# RTS5918 register map
Vendor: Realtek Semiconductor Corp.; Series: RTS5918 Series; File version: 1.00
CPU: ARMV8MML r0p0, little endian, MPU, FPU, VTOR, 3 interrupt priority bits, 8 SAU regions
Registers are 32-bit, read-write, reset 0x0 unless marked. A register's access mark holds for its fields unless they carry their own. Offsets are from the block's base; [hi:lo] are bit positions; {n}, {i} and the like mark numbered series; 'fields as' and 'values as' point back to an identical list.

## ESPI — eSPI Controller
Base 0x40220000
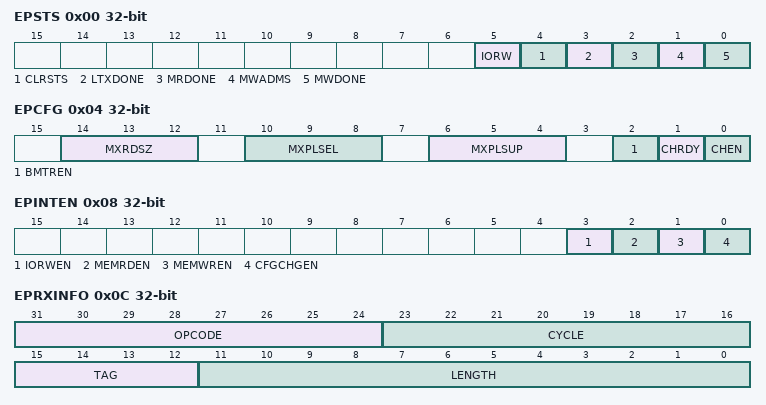
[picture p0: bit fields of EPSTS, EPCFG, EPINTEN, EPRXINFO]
0x00 EPSTS — PERIPHERAL CH. STATUS REGISTER
  [5] IORW write-1-clears — Peripheral Ch. IO R/W Short Status
    0=DO_NOTHING; 1=CLEAR (Clear Peripheral ch. IO R/W Short status)
  [4] CLRSTS write-1-clears — Peripheral Ch. Clear Status
    0=DO_NOTHING; 1=CLEAR (Clear Peripheral ch. status)
  [3] LTXDONE write-1-clears — Peripheral Ch. LTR Message Tx Done
    0=NOT_OCCURRED (Peripheral ch. LTR message tx done is not occurred); 1=OCCURRED (Peripheral ch. LTR message tx done is occurred)
  [2] MRDONE write-1-clears — Peripheral Ch. Memory Read Done
    0=NOT_OCCURRED (Peripheral ch. memory read done is not occurred); 1=OCCURRED (Peripheral ch. memory read done is occurred)
  [1] MWADMS write-1-clears — Peripheral Ch. Memory Address Mismatch
    0=NOT_OCCURRED (Peripheral ch. memory address mismatch is not occurred); 1=OCCURRED (Peripheral ch. memory address mismatch is occurred)
  [0] MWDONE write-1-clears — Peripheral Ch. Memory Write Done
    0=NOT_OCCURRED (Peripheral ch. memory write done is not occurred); 1=OCCURRED (Peripheral ch. memory write done is occurred)
0x04 EPCFG — PERIPHERAL CH. CONFIGURTAION REGISTER
  [14:12] MXRDSZ — Peripheral Ch. Maximum Read Request Size
    1=64B (64 bytes address aligned max read request size); 2=128B (128 bytes address aligned max read request size); 3=256B (256 bytes address aligned max read request size); 4=512B (512 bytes address aligned max read request size); 5=1024B (1024 bytes address aligned max read request size); 6=2048B (2048 bytes address aligned max read request size); 7=4096B (4096 bytes address aligned max read request size); other=NOT_USED (Reserved values. Do not use.)
  [10:8] MXPLSEL — Peripheral Ch. Maximum Payload Size Selected
    1=64B (64 bytes address aligned max payload size); 2=128B (128 bytes address aligned max payload size); 3=256B (256 bytes address aligned max payload size); other=NOT_USED (Reserved values. Do not use.)
  [6:4] MXPLSUP — Peripheral Ch. Maximum Payload Size Supported
    values as MXPLSEL
  [2] BMTREN — Peripheral Ch. Bus Master Enable
    0=DISABLE (Peripheral ch. bus mastering is disable); 1=ENABLE (Peripheral ch. bus mastering is enable)
  [1] CHRDY — Peripheral Ch. Ready
    0=NOT_READY (Peripheral ch. is not ready); 1=READY (Peripheral ch. is ready)
  [0] CHEN — Peripheral Ch. Enable
    0=DISABLE (Peripheral ch. is disable); 1=ENABLE (Peripheral ch. is enable)
0x08 EPINTEN — PERIPHERAL CH. INTERRUPT ENABLE REGISTER
  [3] IORWEN — Peripheral Ch. IO R/W Short Interrupt Enable
    0=DISABLE (Disable peripheral ch. IO R/W Short interrupt); 1=ENABLE (Enable peripheral ch. IO R/W Short interrupt)
  [2] MEMRDEN — Peripheral Ch. Memory Read Interrupt Enable
    0=DISABLE (Disable peripheral ch. memory read interrupt); 1=ENABLE (Enable peripheral ch. memory read interrupt)
  [1] MEMWREN — Peripheral Ch. Memory Write Interrupt Enable
    0=DISABLE (Disable peripheral ch. memory write interrupt); 1=ENABLE (Enable peripheral ch. memory write interrupt)
  [0] CFGCHGEN — Peripheral Ch. Configuration Change Interrupt Enable
    0=DISABLE (Disable peripheral ch. config change interrupt); 1=ENABLE (Enable peripheral ch. config change interrupt)
0x0C EPRXINFO ro — PERIPHERAL CH. RECEIVE PACKET INFORMATION REGISTER
  [31:24] OPCODE — Peripheral Ch. RX Command Opcode
  [23:16] CYCLE — Peripheral Ch. RX Command Cycle
  [15:12] TAG — Peripheral Ch. RX Command Tag
  [11:0] LENGTH — Peripheral Ch. Rx Command Length
0x10 EPRXADRH — PERIPHERAL CH. RECEIVE ADDRESS HIGH REGISTER
0x14 EPRXADRL — PERIPHERAL CH. RECEIVE ADDRESS LOW REGISTER
0x18 EPCPRADR — PERIPHERAL CH. COMPARE ADDRESS REGISTER
0x1C EPCPRVLD — PERIPHERAL CH. COMPARE ADDRESS VALID REGISTER
  [0] VALIDEN — Peripheral Ch. Memory Write Address Compare Enable
    0=IGNORE (Ignore peripheral ch. memory write address); 1=COMAPRE (Compare peripheral ch. memory write address)
0x20 EPBUF — PERIPHERAL CH. BUFFER REGISTER
0x24 EPBUFSZ — PERIPHERAL CH. BUFFER SIZE REGISTER
  [3:0] SIZE — Peripheral Ch. Memory Buffer Size
    0=x16 (x16 payload size); 1=x1 payload size; {v}=x{v} (x{v} payload size) (v=2..9); 10=x10 payload size; 11=x11 payload size; {v}=x{v} (x{v} payload size) (v=12..15)
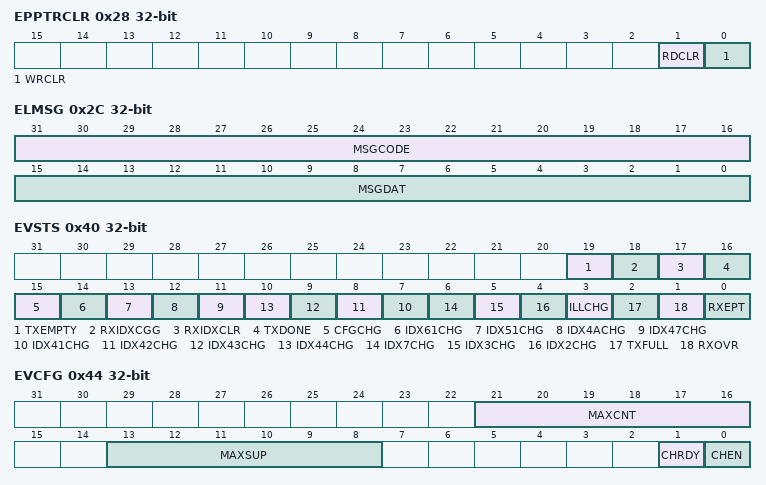
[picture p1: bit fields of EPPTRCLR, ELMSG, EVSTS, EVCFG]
0x28 EPPTRCLR — PERIPHERAL CH. POINTER CLEAR REGISTER
  [1] RDCLR write-1-clears — Reset Peripheral Ch. Memory Read Pointer
    0=DO_NOTHING; 1=RESET (Reset peripheral ch. read pointer)
  [0] WRCLR write-1-clears — Reset Peripheral Ch. Memory Write Pointer
    0=DO_NOTHING; 1=RESET (Reset peripheral ch. write pointer)
0x2C ELMSG — PERIPHERAL CH. LTR MESSAGE REGISTER
  [31:16] MSGCODE — Code of LTR Message to be Transfered
  [15:0] MSGDAT — Data of LTR Message to be Transfered
0x30 EPMRDA — PERIPHERAL CH. MEMORY RECEIVE DATA REGISTER
0x34 EPMRADRL — PERIPHERAL CH. MEMORY RECEIVE ADDRESS LOW REGISTER
0x38 EPMRADRH — PERIPHERAL CH. MEMORY RECEIVE ADDRESS HIGH REGISTER
0x3C EPMRLEN — PERIPHERAL CH. MEMORY RECEIVE LENGTH REGISTER
  [11:0] RXLEN — Peripheral Ch. Memory Receive Length
0x40 EVSTS — VIRTUAL WIRE CH. STATUS REGISTER
  [19] TXEMPTY — Virtual Wire Ch. Tx FIFO Empty
    0=NOT_EMPTY (Virtual wire ch. Tx FIFO is not empty); 1=EMPTY (Virtual wire ch. Tx FIFO is empty)
  [18] RXIDXCGG write-1-clears — Virtual Wire Ch. Rx Changed
  [17] RXIDXCLR write-1-clears — Virtual Wire Ch. Rx Index Clear
  [16] TXDONE write-1-clears — Virtual Wire Ch. Transaction Done
    0=NOT_OCCURRED (Virtual wire ch. transaction done is not occurred); 1=OCCURRED (Virtual wire ch. transaction done is occurred)
  [15] CFGCHG write-1-clears — Virtual Wire Ch. Configuration Changed
    0=NOT_CHANGED (Virtual wire ch. configuration is not changed); 1=CHANGED (Virtual wire ch. configuration is changed)
  [14] IDX61CHG write-1-clears — Virtual Wire Ch. Index61 Changed
    0=NOT_CHANGED (Virtual wire ch. index is not changed); 1=CHANGED (Virtual wire ch. index is changed)
  [13] IDX51CHG write-1-clears — Virtual Wire Ch. Index51 Changed
    values as IDX61CHG
  [12] IDX4ACHG write-1-clears — Virtual Wire Ch. Index4A Changed
    values as IDX61CHG
  [11] IDX47CHG write-1-clears — Virtual Wire Ch. Index47 Changed
    values as IDX61CHG
  [n-34] IDX{n}CHG write-1-clears (n=41..44) — Virtual Wire Ch. Index{n} Changed
    values as IDX61CHG
  [6] IDX7CHG write-1-clears — Virtual Wire Ch. Index7 Changed
    values as IDX61CHG
  [5] IDX3CHG write-1-clears — Virtual Wire Ch. Index3 Changed
    values as IDX61CHG
  [4] IDX2CHG write-1-clears — Virtual Wire Ch. Index2 Changed
    values as IDX61CHG
  [3] ILLCHG write-1-clears — Virtual Wire Ch. Illegal Index
    0=NOT_ILLEGAL (Virtual wire ch. Tx index is not illegal); 1=ILLEGAL (Virtual wire ch. Tx index is illegal)
  [2] TXFULL ro — Virtual Wire Ch. Tx FIFO Full
    0=NOT_FULL (Virtual wire ch. Tx FIFO is not full); 1=FULL (Virtual wire ch. Tx FIFO is full)
  [1] RXOVR write-1-clears — Virtual Wire Ch. Rx FIFO Overrun
    0=NOT_OV (Virtual wire ch. Rx FIFO is not overrun); 1=OV (Virtual wire ch. Rx FIFO is overrun)
  [0] RXEPT ro — Virtual Wire Ch. Rx FIFO Empty
    0=NOT_EMPTY (Virtual wire ch. Rx FIFO is not empty); 1=EMPTY (Virtual wire ch. Rx FIFO is empty)
0x44 EVCFG — VIRTUAL WIRE CH. CONFIGURATION REGISTER
  [21:16] MAXCNT ro — Virtual Wire Ch. Maximum Operating Count
  [13:8] MAXSUP ro — Virtual Wire Ch. Maximum Count Supported
  [1] CHRDY — Virtual Wire Ch. Ready
    0=NOT_READY (Virtual Wire ch. is not ready); 1=READY (Virtual Wire ch. is ready)
  [0] CHEN — Virtual Wire Ch. Enable
    0=DISABLE (Virtual Wire ch. is disable); 1=ENABLE (Virtual Wire ch. is enable)
0x48 EVIDX2 — VIRTUAL WIRE CH. RX INDEX 2 REGISTER
  [7:0] RXDAT ro — Virtual Wire Ch. Index2 Receive Data
0x4C EVIDX3 — VIRTUAL WIRE CH. RX INDEX 3 REGISTER
  [7:0] RXDAT ro — Virtual Wire Ch. Index3 Receive Data
0x50 EVIDX7 — VIRTUAL WIRE CH. RX INDEX 7 REGISTER
  [7:0] RXDAT ro — Virtual Wire Ch. Index7 Receive Data
0x54 EVIDX41 — VIRTUAL WIRE CH. RX INDEX 41 REGISTER
  [7:0] RXDAT ro — Virtual Wire Ch. Index41 Receive Data
0x58 EVIDX42 — VIRTUAL WIRE CH. RX INDEX 42 REGISTER
  [7:0] RXDAT ro — Virtual Wire Ch. Index42 Receive Data
0x5C EVIDX43 — VIRTUAL WIRE CH. RX INDEX 43 REGISTER
  [7:0] RXDAT ro — Virtual Wire Ch. Index43 Receive Data
0x60 EVIDX44 — VIRTUAL WIRE CH. RX INDEX 44 REGISTER
  [7:0] RXDAT ro — Virtual Wire Ch. Index44 Receive Data
0x64 EVIDX47 — VIRTUAL WIRE CH. RX INDEX 47 REGISTER
  [7:0] RXDAT ro — Virtual Wire Ch. Index47 Receive Data
0x68 EVIDX4A — VIRTUAL WIRE CH. RX INDEX 4A REGISTER
  [7:0] RXDAT ro — Virtual Wire Ch. Index4A Receive Data
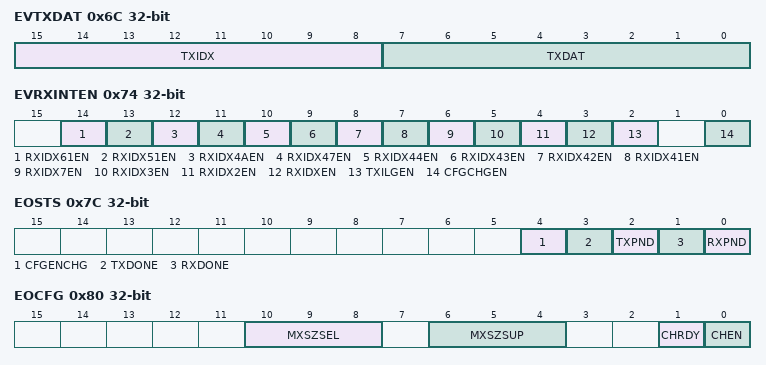
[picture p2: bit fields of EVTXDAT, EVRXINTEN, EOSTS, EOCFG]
0x6C EVTXDAT — VIRTUAL WIRE CH. TX DATA REGISTER
  [15:8] TXIDX — Virtual Wire Ch. Transport Index
  [7:0] TXDAT — Virtual Wire Ch. Transport Data
0x70 EVPVIDX — VIRTUAL WIRE CH. PRIVILEGE INDEX REGISTER
  [7:0] PVIDX ro — Virtual Wire Ch. Transport Privilege Index
0x74 EVRXINTEN — VIRTUAL WIRE CH. RX INTERRUPT ENABLE REGISTER
  [14] RXIDX61EN — Virtual Wire Ch. Recevie Index61 Data Change Interrupt Enable
    0=DISABLE (Disable virtual wire ch. recevice index61 data change interrupt); 1=ENABLE (Enable virtual wire ch. recevice index61 data change interrupt)
  [13] RXIDX51EN — Virtual Wire Ch. Recevie Index51 Data Change Interrupt Enable
    0=DISABLE (Disable virtual wire ch. recevice index51 data change interrupt); 1=ENABLE (Enable virtual wire ch. recevice index51 data change interrupt)
  [12] RXIDX4AEN — Virtual Wire Ch. Recevie Index4A Data Change Interrupt Enable
    0=DISABLE (Disable virtual wire ch. recevice index4A data change interrupt); 1=ENABLE (Enable virtual wire ch. recevice index4A data change interrupt)
  [11] RXIDX47EN — Virtual Wire Ch. Recevie Index47 Data Change Interrupt Enable
    0=DISABLE (Disable virtual wire ch. recevice index47 data change interrupt); 1=ENABLE (Enable virtual wire ch. recevice index47 data change interrupt)
  [10] RXIDX44EN — Virtual Wire Ch. Recevie Index44 Data Change Interrupt Enable
    0=DISABLE (Disable virtual wire ch. recevice index43 data change interrupt); 1=ENABLE (Enable virtual wire ch. recevice index44 data change interrupt)
  [9] RXIDX43EN — Virtual Wire Ch. Recevie Index43 Data Change Interrupt Enable
    0=DISABLE (Disable virtual wire ch. recevice index43 data change interrupt); 1=ENABLE (Enable virtual wire ch. recevice index43 data change interrupt)
  [8] RXIDX42EN — Virtual Wire Ch. Recevie Index42 Data Change Interrupt Enable
    0=DISABLE (Disable virtual wire ch. recevice index42 data change interrupt); 1=ENABLE (Enable virtual wire ch. recevice index42 data change interrupt)
  [7] RXIDX41EN — Virtual Wire Ch. Recevie Index41 Data Change Interrupt Enable
    0=DISABLE (Disable virtual wire ch. recevice index41 data change interrupt); 1=ENABLE (Enable virtual wire ch. recevice index41 data change interrupt)
  [6] RXIDX7EN — Virtual Wire Ch. Recevie Index7 Data Change Interrupt Enable
    0=DISABLE (Disable virtual wire ch. recevice index7 data change interrupt); 1=ENABLE (Enable virtual wire ch. recevice index7 data change interrupt)
  [5] RXIDX3EN — Virtual Wire Ch. Recevie Index3 Data Change Interrupt Enable
    0=DISABLE (Disable virtual wire ch. recevice index3 data change interrupt); 1=ENABLE (Enable virtual wire ch. recevice index3 data change interrupt)
  [4] RXIDX2EN — Virtual Wire Ch. Recevie Index2 Data Change Interrupt Enable
    0=DISABLE (Disable virtual wire ch. recevice index2 data change interrupt); 1=ENABLE (Enable virtual wire ch. recevice index2 data change interrupt)
  [3] RXIDXEN — Virtual Wire Ch. Recevie Other Index Data Change Interrupt Enable
    0=DISABLE (Disable virtual wire ch. recevice other index data change interrupt); 1=ENABLE (Enable virtual wire ch. recevice other index data change interrupt)
  [2] TXILGEN — Virtual Wire Ch. TX Illegal Interrupt Enable
    0=DISABLE (Disable virtual wire TX Illegal interrupt); 1=ENABLE (Enable virtual wire TX Illegal interrupt)
  [0] CFGCHGEN — Virtual Wire Ch. Configuration Change Interrupt Enable
    0=DISABLE (Disable virtual wire ch. config change interrupt); 1=ENABLE (Enable virtual wire ch. config change interrupt)
0x78 EVTXINTEN — VIRTUAL WIRE CH. TX INTERRUPT ENABLE REGISTER
  [0] TXMPTEN — Virtual Wire Ch. Tx FIFO Empty Interrupt Enable
    0=DISABLE (Disable virtual wire ch. tx FIFO empty interrupt); 1=ENABLE (Enable virtual wire ch. tx FIFO empty interrupt)
0x7C EOSTS — OOB CH. STATUS REGISTER
  [4] CFGENCHG — OOB Ch. Configuration Channel Enable Changed
    0=NOT_OCCURRED (OOB ch. configuration channel enable changed is not occurred); 1=OCCURRED (OOB ch. configuration channel enable changed is occurred)
  [3] TXDONE write-1-clears — OOB Ch. Transaction Done
    0=NOT_OCCURRED (OOB ch. transaction done is not occurred); 1=OCCURRED (OOB ch. transaction done is occurred)
  [2] TXPND ro — OOB Ch. TX FIFO Pending
    0=NOT_PENDING (Have no data in Tx FIFO); 1=PENDING (Have data in Tx FIFO, waiting for transaction)
  [1] RXDONE write-1-clears — OOB Ch. Receive Done
    0=NOT_OCCURRED (OOB ch. recevie done is not occurred); 1=OCCURRED (OOB ch. recevie done is occurred)
  [0] RXPND ro — OOB Ch. RX FIFO Pending
    0=NOT_PENDING (Have no data in Rx FIFO); 1=PENDING (Have data in Rx FIFO)
0x80 EOCFG — OOB CH. CONFIGURATION REGISTER
  [10:8] MXSZSEL ro — OOB Ch. Maximum Payload Size Selected
    1=64B (64 bytes max payload size); 2=128B (128 bytes max payload size); 3=256B (256 bytes max payload size); other=NOT_USED (Reserved values. Do not use.)
  [6:4] MXSZSUP ro — OOB Ch. Maximum Payload Size Supported
    values as MXSZSEL
  [1] CHRDY — OOB Ch. Ready
    0=NOT_READY (OOB ch. is not ready); 1=READY (OOB ch. is ready)
  [0] CHEN — OOB Ch. Enable
    0=DISABLE (OOB ch. is disable); 1=ENABLE (OOB ch. is enable)
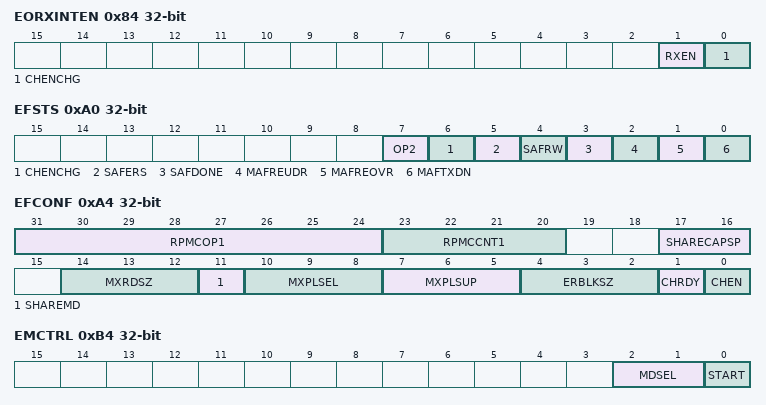
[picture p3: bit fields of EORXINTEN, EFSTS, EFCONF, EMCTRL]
0x84 EORXINTEN — OOB CH. RX INTERRUPT ENABLE REGISTER
  [1] RXEN — OOB Ch. Rx Interrupt Enable
    0=DISABLE (Disable OOB ch. rx interrupt); 1=ENABLE (Enable OOB ch. rx interrupt)
  [0] CHENCHG — OOB Ch. Configuration Channel Enable Changed Interrupt Enable
    0=DISABLE (Disable OOB ch. configuration channel enable changed interrupt); 1=ENABLE (Enable OOB ch. configuration channel enable changed interrupt)
0x88 EORXBUF — OOB CH. RX BUFFER REGISTER
0x8C EORXLEN — OOB CH. RX LENGTH REGISTER
  [11:0] LENGTH — OOB Ch. Rx Length
0x90 EOTXBUF — OOB CH. TX BUFFER REGISTER
0x94 EOTXLEN — OOB CH. TX LENGTH REGISTER
  [7:0] LENGTH — OOB Ch. Tx Length
0x98 EOTXCTRL — OOB CH. TX CONTROL REGISTER
  [0] TXSTR — Kick OOB Ch. Start to Transaction
0x9C EOTXINTEN — OOB CH. TX INTERRUPT ENABLE REGISTER
  [0] TXEN — OOB Ch. Tx Interrupt Enable
    0=DISABLE (Disable OOB ch. tx interrupt); 1=ENABLE (Enable OOB ch. tx interrupt)
0xA0 EFSTS — FLASH CH. STATUS REGISTER
  [7] OP2 — Flash Ch. Receive RPMC OP2 Command
    0=NOT_OCCURRED (Flash Ch. have not received RPMC OP2 command); 1=OCCURRED (Flash Ch. have received RPMC OP2 command)
  [6] CHENCHG — Flash Ch. Configuration Channel Enable Changed
    0=NOT_OCCURRED (Flash ch. configuration channel enable changed is not occurred); 1=OCCURRED (Flash ch. configuration channel enable changed is occurred)
  [5] SAFERS write-1-clears — Flash Ch. SAF Transfer Type Erase
    0=NOT_OCCURRED (Flash ch. SAF transfer type erase is not occurred); 1=OCCURRED (Flash ch. SAF transfer type erase is occurred)
  [4] SAFRW — Flash Ch. SAF Transfer Type
    0=READ (Flash ch. SAF transfer type is read); 1=WRITE (Flash ch. SAF transfer type is write)
  [3] SAFDONE write-1-clears — Flash Ch. SAF Transfer Done
    0=NOT_OCCURRED (Flash ch. SAF transfer done is not occurred); 1=OCCURRED (Flash ch. SAF transfer done is occurred)
  [2] MAFREUDR write-1-clears — Flash Ch. MAF Underrun
    0=NOT_OCCURRED (Flash ch. MAF underrun is not occurred); 1=OCCURRED (Flash ch. MAF underrun is occurred)
  [1] MAFREOVR write-1-clears — Flash Ch. MAF Overrun
    0=NOT_OCCURRED (Flash ch. MAF overrun is not occurred); 1=OCCURRED (Flash ch. MAF overrun is occurred)
  [0] MAFTXDN write-1-clears — Flash Ch. MAF Transfer Done
    0=NOT_OCCURRED (Flash ch. MAF transfer done is not occurred); 1=OCCURRED (Flash ch. MAF transfer done is occurred)
0xA4 EFCONF — FLASH CH. CONFIGURATION REGISTER
  [31:24] RPMCOP1 — RPMC OP1 Opcode on the 1st RPMC Flash device
  [23:20] RPMCCNT1 — RPMC Counter on the 1st RPMC Flash device
  [17:16] SHARECAPSP — Flash Sharing Capability Supported
    2=SAF (Target attached flash sharing supported); 3=SAF_MAF (Both target/controller attached flash sharing supported); other=MAF (Controller attached flash sharing supported)
  [14:12] MXRDSZ — Flash Access Channel Maximum Read Request Size
    values as EPCFG.MXRDSZ
  [11] SHAREMD — Flash Sharing Mode
    0=MAF (Controller attached flash sharing); 1=SAF (Target attached flash sharing)
  [10:8] MXPLSEL — Flash Access Channel Maximum Payload Size Selected
    1=64KB (64 bytes max payload size); 2=128KB (128 bytes max payload size); 3=256KB (256 bytes max payload size); other=NOT_USED (Reserved values. Do not use.)
  [7:5] MXPLSUP — Flash Access Channel Maximum Payload Size Supported
    values as MXPLSEL
  [4:2] ERBLKSZ — Flash Block Erase Size
    1=4KB (4 Kbytes); 2=64KB (64 Kbytes); 3=4KB_64KB (Both 4 Kbytes and 64 Kbytes); 4=128KB (128 Kbytes); 5=256KB (256 Kbytes); other=NOT_USED (Reserved values. Do not use.)
  [1] CHRDY — Flash Access Ch. Ready
    0=NOT_READY (Flash access ch. is not ready); 1=READY (Flash access ch. is ready)
  [0] CHEN — Flash Access Ch. Enable
    0=DISABLE (Flash access ch. is disable); 1=ENABLE (Flash access ch. is enable)
0xA8 EMADR — FLASH CH. MAF FLASH ADDRESS REGISTER
0xAC EMTRLEN — FLASH CH. MAF TRANSFER LENGTH REGISTER
  [11:0] TRLEN — Flash Ch. MAF Tx Length
0xB0 EMBUF — FLASH CH. MAF BUFFER REGISTER
0xB4 EMCTRL — FLASH CH. MAF CONTROL REGISTER
  [2:1] MDSEL — Flash Ch. MAF TR Mode selection
    0=TR_READ (Perform MAF read transaction); 1=TR_WRITE (Perform MAF write transactiond); 2=TR_ERASE (Perform MAF erase transaction); other=NOT_USED (Reserved values. Do not use.)
  [0] START — Kick Flash Ch. MAF Start to Transaction
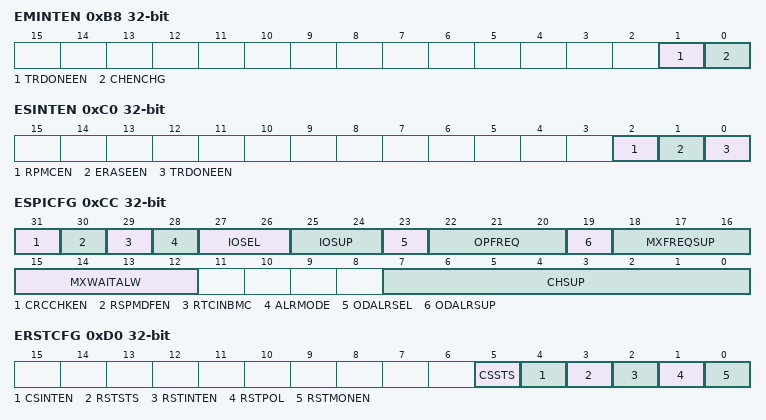
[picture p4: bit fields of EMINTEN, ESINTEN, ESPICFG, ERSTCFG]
0xB8 EMINTEN — FLASH CH. MAF INTERRUPT ENABLE REGISTER
  [1] TRDONEEN — Flash Ch. MAF Transfer Done Interrupt Enable
    0=DISABLE (Disable flash ch. MAF transfer done interrupt); 1=ENABLE (Enable flash ch. MAF transfer done interrupt)
  [0] CHENCHG — Flash Ch. Configuration Channel Enable Changed Interrupt Enable
    0=DISABLE (Disable flash ch. configuration channel enable changed interrupt); 1=ENABLE (Enable flash ch. configuration channel enable changed interrupt)
0xBC ESBUF — FLASH CH. SAF BUFFER REGISTER #0
0xC0 ESINTEN — FLASH CH. SAF INTERRUPT ENABLE REGISTER
  [2] RPMCEN — Flash Ch. SAF RPMC OP2 Interrupt Enable
    0=DISABLE (Disable flash ch. SAF RPMC op2 interrupt); 1=ENABLE (Enable flash ch. SAF RPMC op2 interrupt)
  [1] ERASEEN — Flash Ch. SAF Erase Interrupt Enable
    0=DISABLE (Disable flash ch. SAF erase interrupt); 1=ENABLE (Enable flash ch. SAF erase interrupt)
  [0] TRDONEEN — Flash Ch. SAF Transfer Done Interrupt Enable
    0=DISABLE (Disable flash ch. SAF transfer done interrupt); 1=ENABLE (Enable flash ch. SAF transfer done interrupt)
0xC4 ESRXADR — FLASH CH. SAF RECEIVE ADDRESS REGISTER
0xC8 ESRXLEN — FLASH CH. SAF RECEIVE LENGTH REGISTER
  [11:0] LENGTH ro — Peripheral Ch. RX Command Length
0xCC ESPICFG — GENERAL CONFIGURATION REGISTER
  [31] CRCCHKEN — CRC Checking Enable
    0=DISABLE (Disable CRC checking); 1=ENABLE (Enable CRC checking)
  [30] RSPMDFEN — Response Modifier Enable
    0=DISABLE (Disable the use of Response Modifier); 1=ENABLE (Enable the use of Response Modifier)
  [29] RTCINBMC — RTC-Integrated-BMC
    0=NOT_SUPPORTED (BMC does not support an integrated RTC); 1=SUPPORTED (BMC supports an integrated RTC)
  [28] ALRMODE — Alert Mode
    0=IO1_PIN (I/O[1] pin is used to signal the alert event); 1=ALERT_PIN (Alert# pin is used to signal the alert event)
  [27:26] IOSEL — I/O Mode Select
    0=SINGLE (Single I/O Select); 1=DUAL (Dual I/O Select); 2=QUAD (Quad I/O Select); other=NOT_USED (Reserved values. Do not use.)
  [25:24] IOSUP — I/O Mode Support
    0=SINGLE (Single I/O supported); 1=SINGLE_DUAL (Single and Dual I/O supported); 2=SINGLE_QUAD (Single and Quad I/O supported); 3=SINGLE_DUAL_QUAD (Single, Dual and Dual I/O supported)
  [23] ODALRSEL — Open Drain Alert Select
    0=OUTPUT (Alert# pin is a driven output); 1=OPEN_DRAIN (Alert# pin is an open-drain output)
  [22:20] OPFREQ — Operating Frequency
    0=20MHz (Operating frequency is 20MHz); 1=25MHz (Operating frequency is 25MHz); 2=33MHz (Operating frequency is 33MHz); 3=50MHz (Operating frequency is 50MHz); 4=66MHz (Operating frequency is 66MHz); other=NOT_USED (Reserved values. Do not use.)
  [19] ODALRSUP — Open Drain Alert Supported
    0=NOT_SUPPORTED (Open-drain Alert# pin is not supported); 1=SUPPORTED (Open-drain Alert# pin is supported)
  [18:16] MXFREQSUP — Maximum Frequency Supported
    0=20MHz (Maximum operating frequency is 20MHz); 1=25MHz (Maximum operating frequency is 25MHz); 2=33MHz (Maximum operating frequency is 33MHz); 3=50MHz (Maximum operating frequency is 50MHz); 4=66MHz (Maximum operating frequency is 66MHz); other=NOT_USED (Reserved values. Do not use.)
  [15:12] MXWAITALW — Maximum WAIT STATE Allowed
  [7:0] CHSUP — Channel Supported
0xD0 ERSTCFG — RESET PIN INTERRUPT CONFIGURATION REGISTER
  [5] CSSTS — eSPI CS Pin Status
  [4] CSINTEN — eSPI CS Pin Interrupt Enable
    0=DISABLE (Disable eSPI CS pin interrupt); 1=ENABLE (Enable eSPI CS pin interrupt)
  [3] RSTSTS — eSPI Reset Pin Status
  [2] RSTINTEN — eSPI Reset Pin Interrupt Enable
    0=DISABLE (Disable eSPI reset pin interrupt); 1=ENABLE (Enable eSPI reset pin interrupt)
  [1] RSTPOL — eSPI Reset Pin Polarity
    0=RISING (Rising-edge(low-to-high) on reset pin trigger interrupt); 1=FALLING (Falling-edge(high-to-low) on reset pin trigger interrupt)
  [0] RSTMONEN — eSPI Reset Pin Monitor Enable
    0=DISABLE (Disable eSPI reset pin monitor); 1=ENABLE (Enable eSPI reset pin monitor)
0xD4 EVIDX51 — VIRTUAL WIRE CH. RX INDEX 51 REGISTER
  [7:0] RXDAT ro — Virtual Wire Ch. Index51 Receive Data
0xD8 EVIDX61 — VIRTUAL WIRE CH. RX INDEX 61 REGISTER
  [7:0] RXDAT ro — Virtual Wire Ch. Index61 Receive Data
0xDC ESRXC — FLASH CH. SAF RECEIVE CYCLE TYPE REGISTER
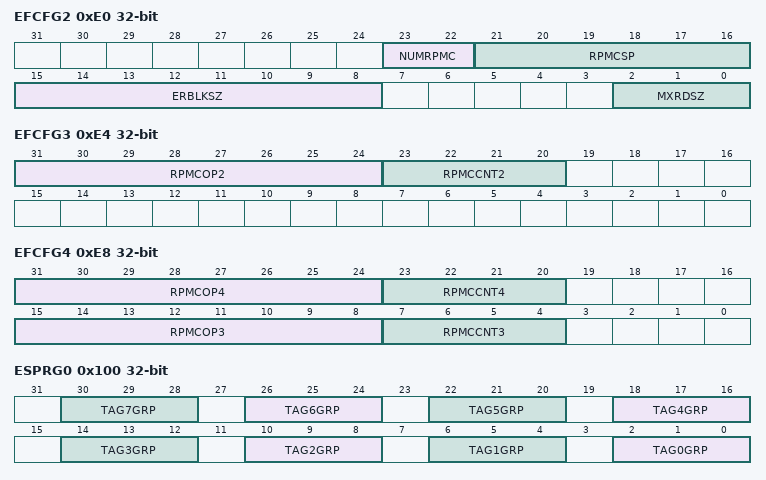
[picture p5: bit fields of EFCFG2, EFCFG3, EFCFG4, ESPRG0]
0xE0 EFCFG2 — FLASH CH. SAF CONFIG #2 REGISTER
  [23:22] NUMRPMC — Number of Target Attached Flash RPMC flash devices
    0=x1 RPMC flash device is supported; 1=x2 (x2 RPMC flash device is supported); 2=x3 (x3 RPMC flash device is supported); 3=x4 (x4 RPMC flash device is supported)
  [21:16] RPMCSP — Target RPMC Supported
  [15:8] ERBLKSZ — Target Flash Erase Block Size
  [2:0] MXRDSZ — Target Maximum Read Request Size Supported
    2=128B (128 bytes max read request size); 3=256B (256 bytes max read request size); 4=512B (512 bytes max read request size); 5=1024B (1024 bytes max read request size); 6=2048B (2048 bytes max read request size); 7=4096B (4096 bytes max read request size); other=64B (64 bytes max read request size)
0xE4 EFCFG3 — FLASH CH. SAF CONFIG #3 REGISTER
  [31:24] RPMCOP2 — RPMC OP1 Opcode on the 2nd RPMC Flash device
  [23:20] RPMCCNT2 — RPMC Counter on the 2nd RPMC Flash device
0xE8 EFCFG4 — FLASH CH. SAF CONFIG #4 REGISTER
  [31:24] RPMCOP4 — RPMC OP1 Opcode on the 4th RPMC Flash device
  [23:20] RPMCCNT4 — RPMC Counter on the 4th RPMC Flash device
  [15:8] RPMCOP3 — RPMC OP1 Opcode on the 3rd RPMC Flash device
  [7:4] RPMCCNT3 — RPMC Counter on the 3rd RPMC Flash device
0xF8 ELCTRL — PERIPHERAL CH. LTR CONTROL REGISTER
  [0] TXSTR — Kick LTR Start to Transaction
0xFC ESBUF1 — FLASH CH. SAF RPMC BUFFER1 REGISTER
0x100 ESPRG0 — FLASH CH. SAF PROTECTION GROUP #0 REGISTER
  [4n+2:4n] TAG{n}GRP (n=0..7) — Tag #{n} Group
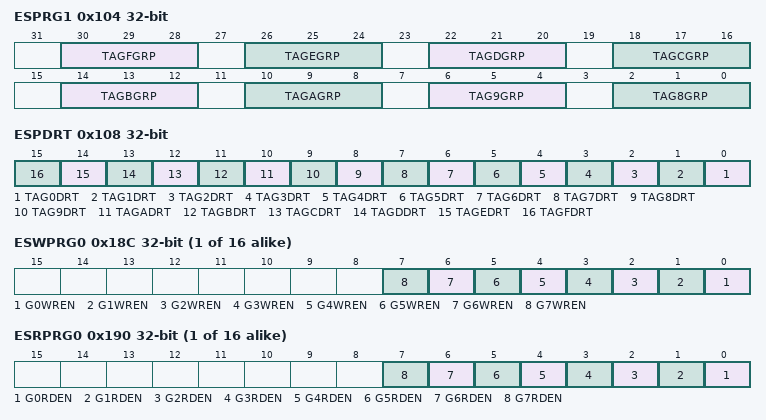
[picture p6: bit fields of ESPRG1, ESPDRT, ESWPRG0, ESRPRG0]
0x104 ESPRG1 — FLASH CH. SAF PROTECTION GROUP #1 REGISTER
  [30:28] TAGFGRP — Tag #F Group
  [26:24] TAGEGRP — Tag #E Group
  [22:20] TAGDGRP — Tag #D Group
  [18:16] TAGCGRP — Tag #C Group
  [14:12] TAGBGRP — Tag #B Group
  [10:8] TAGAGRP — Tag #A Group
  [6:4] TAG9GRP — Tag #9 Group
  [2:0] TAG8GRP — Tag #8 Group
0x108 ESPDRT — FLASH CH. SAF PROTECTION DIRTY REGISTER
  [0] TAG{x}DRT (x=0,1,2,3,4,5,6,7,8,9,A,B,C,D,E,F; step 1) — Tag #{x} Dirty
    0=NOT_DIRTY (Contents of Region are not dirty); 1=DIRTY (Contents of Region are dirty)
0x10C ESP{x}STR (x=0,1,2,3,4,5,6,7,8,9,A,B,C,D,E,F; step 0x4) — FLASH CH. SAF REGION #{x} START REGISTER
  [19:0] ADDR — Region Start Address
0x14C ESP{x}LEN (x=0,1,2,3,4,5,6,7,8,9,A,B,C,D,E,F; step 0x4) — FLASH CH. SAF REGION #{x} LENGTH REGISTER
  [19:0] LEN — Region Length
0x18C ESWPRG{x} (x=0,1,2,3,4,5,6,7,8,9,A,B,C,D,E,F; step 0x8) — FLASH CH. SAF WRITE PROTECTION REGION #{x} REGISTER
  [n] G{n}WREN (n=0..7) — Group #{n} Write Enable
0x190 ESRPRG{x} (x=0,1,2,3,4,5,6,7,8,9,A,B,C,D,E,F; step 0x8) — FLASH CH. SAF READ PROTECTION REGION #{x} REGISTER
  [n] G{n}RDEN (n=0..7) — Group #{n} Read Enable
0x20C ESPREN — FLASH CH. SAF PROTECTION ENABLE REGISTER
  [0] EN — Flash Ch. SAF Protection Enable
    0=DISABLE (Disable flash ch. SAF protection); 1=ENABLE (Enable flash ch. SAF protection)
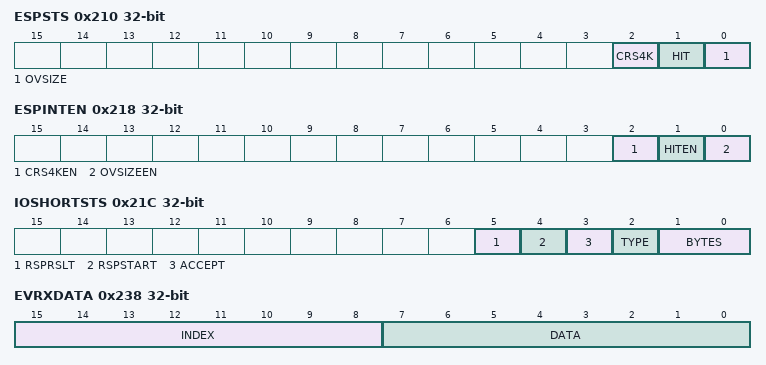
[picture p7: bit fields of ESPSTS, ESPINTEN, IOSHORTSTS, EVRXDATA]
0x210 ESPSTS — FLASH CH. SAF PROTECTION STATUS REGISTER
  [2] CRS4K write-1-clears — Host Cross 4K boundary
    0=NOT_OCCURRED (Host cross 4K boundary is not occurred); 1=OCCURRED (Host cross 4K boundary is occurred)
  [1] HIT write-1-clears — Host Hit Protection Region
    0=NOT_OCCURRED (Host hit protection region is not occurred); 1=OCCURRED (Host hit protection region is occurred)
  [0] OVSIZE write-1-clears — Host Access Over Size
    0=NOT_OCCURRED (Host access over size is not occurred); 1=OCCURRED (Host access over size is occurred)
0x214 ESFLSZ — FLASH CH. SAF FLASH SIZE REGISTER
0x218 ESPINTEN — FLASH CH. SAF PROTECTION INTERRUPT ENABLE REGISTER
  [2] CRS4KEN write-1-clears — Host Cross 4K Boundary Interrupt Enable
    0=DISABLE (Disable host cross 4K boundary interrupt); 1=ENABLE (Enable cross 4K boundary interrupt)
  [1] HITEN write-1-clears — Host Hit Protection Region Interrupt Enable
    0=DISABLE (Disable host hit protection region interrupt); 1=ENABLE (Enable host hit protection region interrupt)
  [0] OVSIZEEN write-1-clears — Host Access Over Size Interrupt Enable
    0=DISABLE (Disable host access over size interrupt); 1=ENABLE (Enable host access over size interrupt)
0x21C IOSHORTSTS — IO SHORT STATUS REGISTER
  [5] RSPRSLT — IO Short Read/Write Response Result
    0=SUCCESS (IO short read/write response successful); 1=UNSUCCESS (IO short read/write response unsuccessful)
  [4] RSPSTART — IO Short Read/Write Response Start
    0=NONE (IO short read/write response pending); 1=START (IO short read/write response start)
  [3] ACCEPT write-1-clears — IO Short Read/Write Accpeted
    0=NOT_OCCURRED (IO short read/write accpeted is not occurred); 1=OCCURRED (IO short read/write accpeted is occurred)
  [2] TYPE — Type of IO Short
    0=READ (Peripheral read); 1=WRITE (Peripheral write)
  [1:0] BYTES — Number of IO Short Bytes
    0=x1 byte; 1=x2 (x2 bytes); 3=x4 (x4 bytes); other=NOT_USED (Reserved values. Do not use.)
0x220 IOSHORTRDADDR — IO SHORT READ ADDRESS REGISTER
  [15:0] ADDR — Channel Address
0x224 IOSHORTRDDATA — IO SHORT DATA REGISTER
0x228 LDNCFG — LDN INDEX/DATA CONFIGURATION REGISTER
  [15:0] IDX — LDN Index Compare Address
0x22C ID0 — CHIP ID #0 REGISTER
0x230 ID1 — CHIP ID #1 REGISTER
0x234 VER — CHIP VERSION REGISTER
0x238 EVRXDATA ro — VW RX INDEX AND DATA REGISTER
  [15:8] INDEX — VW RX Index
  [7:0] DATA — VW RX Data
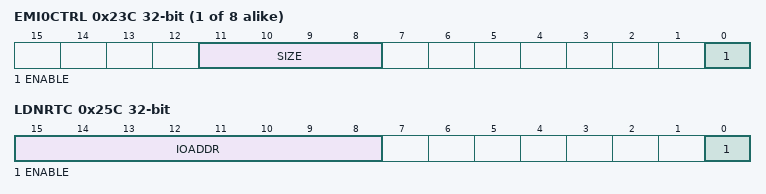
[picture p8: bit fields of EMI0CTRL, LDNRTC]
{0x23C+4i} EMI{i}CTRL (i=0..7) — LDN EMI{i} CONTROL REGISTER
  [11:8] SIZE — EMI Size Selecttion
    0=16BYTES (Region is 16 Bytes); 1=32BYTES (Region is 32 Bytes); 2=64BYTES (Region is 64 Bytes); 3=128BYTES (Region is 128 Bytes); 4=256BYTES (Region is 256 Bytes); 5=512BYTES (Region is 512 Bytes); 6=1024BYTES (Region is 1024 Bytes); 7=2048BYTES (Region is 2048 Bytes); 8=4096BYTES (Region is 4096 Bytes)
  [0] ENABLE — EMI0 Enable
    0=DISABLE (Disable EMI0); 1=ENABLE (Enable EMI0)
0x25C LDNRTC — LDN RTC CCONTROL REGISTER
  [15:8] IOADDR — IO Port Address
  [0] ENABLE — LDN RTC Enable
    0=DISABLE (Disable EMI0); 1=ENABLE (Enable EMI0)
0x260 LDNRTCSAR — LDN RTC BUFFER REGISTER
0x264 DIO0ADDR — DIO 0 MAPPING ADDRESS REGISTER
0x268 DIO1ADDR — DIO 1 MAPPING ADDRESS REGISTER
